# STM32MP13xx register map
File version: 1.5
CPU: CA7 r0p0, little endian, MPU, FPU, 4 interrupt priority bits
Registers are 32-bit, read-write, reset 0x0 unless marked. A register's access mark holds for its fields unless they carry their own. Offsets are from the block's base; [hi:lo] are bit positions; {n}, {i} and the like mark numbered series; 'fields as' and 'values as' point back to an identical list.

## RCC (part 4 of 7)
Base 0x50000000
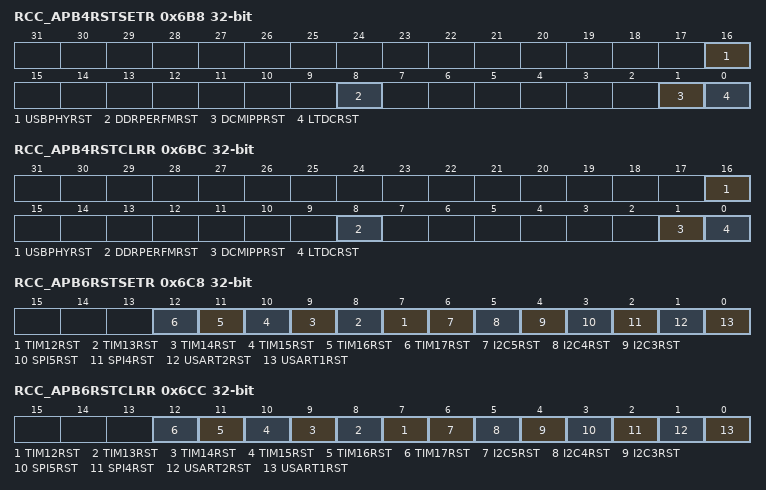
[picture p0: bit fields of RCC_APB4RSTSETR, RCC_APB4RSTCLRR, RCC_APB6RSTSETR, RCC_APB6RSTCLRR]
0x6B8 RCC_APB4RSTSETR — This register may be separately and securely write-protected at a field level, as detailed in the following register fields description. This register is used to activate the reset of the corresponding peripheral. Writing '0' has no effect, reading will return the effective values of the corresponding bits. Writing a '1' activates the reset of the corresponding peripheral.
  [all] fields
    0=Writing '0' has no effect, reading '0' means that the block reset is released; 1=Writing '1' asserts the block reset, reading '1' means that the block reset is asserted
  [16] USBPHYRST — USBPHYC block reset If USB PHY is configured as secure via the corresponding DECPROT[1] field of the ETZPC register, a write access to this register field must be secure. A read access may be secure or non-secure. Set by software.
  [8] DDRPERFMRST — DDRPERFM block reset Set by software.
  [1] DCMIPPRST — DCMIPP block reset If DCMIPP is configured as secure via the corresponding DECPROT[1] field of the ETZPC register, a write access to this register field must be secure. A read access may be secure or non-secure. Set by software.
  [0] LTDCRST — LTDC block reset If LTDC is configured as secure via the corresponding DECPROT[1] field of the ETZPC register, a write access to this register field must be secure. A read access may be secure or non-secure. Set by software.
0x6BC RCC_APB4RSTCLRR — This register may be separately and securely write-protected at a field level, as detailed in the following register fields description. This register is used to release the reset of the corresponding peripheral. Writing '0' has no effect, reading will return the effective values of the corresponding bits. Writing a '1' releases the reset of the corresponding peripheral.
  [all] fields
    0=Writing '0' has no effect, reading '0' means that the block reset is released; 1=Writing '1' releases the block reset, reading '1' means that the block reset is asserted
  [16] USBPHYRST — USBPHYC block reset If USB PHY is configured as secure via the corresponding DECPROT[1] field of the ETZPC register, a write access to this register field must be secure. A read access may be secure or non-secure. Cleared by software.
  [8] DDRPERFMRST — DDRPERFM block reset Cleared by software.
  [1] DCMIPPRST — DCMIPP block reset If DCMIPP is configured as secure via the corresponding DECPROT[1] field of the ETZPC register, a write access to this register field must be secure. A read access may be secure or non-secure. Cleared by software.
  [0] LTDCRST — LTDC block reset If LTDC is configured as secure via the corresponding DECPROT[1] field of the ETZPC register, a write access to this register field must be secure. A read access may be secure or non-secure. Cleared by software.
0x6C0 RCC_APB5RSTSETR — This register may be separately and securely write-protected at a field level depending on the secure state of the corresponding peripheral, i.e. depending on the corresponding DECPROT[1] field of the ETZPC register. This register is used to activate the reset of the corresponding peripheral. Writing '0' has no effect, reading will return the effective values of the corresponding bits. Writing a '1' activates the reset of the corresponding peripheral.
  [20] STGENRST — STGEN block reset If STGENC (STGEN controller sub-part) is configured as secure via the corresponding DECPROT[1] field of the ETZPC register, a write access to this register field must be secure. A read access may be secure or non-secure. Set by software.
    values as the fields of RCC_APB4RSTSETR
0x6C4 RCC_APB5RSTCLRR — This register may be separately and securely write-protected at a field level depending on the secure state of the corresponding peripheral, i.e. depending on the corresponding DECPROT[1] field of the ETZPC register. This register is used to release the reset of the corresponding peripheral. Writing '0' has no effect, reading will return the effective values of the corresponding bits. Writing a '1' releases the reset of the corresponding peripheral.
  [20] STGENRST — STGEN block reset If STGENC (STGEN controller sub-part) is configured as secure via the corresponding DECPROT[1] field of the ETZPC register, a write access to this register field must be secure. A read access may be secure or non-secure. Cleared by software.
    values as the fields of RCC_APB4RSTCLRR
0x6C8 RCC_APB6RSTSETR — This register may be separately and securely write-protected at a field level depending on the secure state of the corresponding peripheral, i.e. depending on the corresponding DECPROT[1] field of the ETZPC register. This register is used to activate the reset of the corresponding peripheral. Writing '0' has no effect, reading will return the effective values of the corresponding bits. Writing a '1' activates the reset of the corresponding peripheral.
  [all] fields
    values as the fields of RCC_APB4RSTSETR
  [n-5] TIM{n}RST (n=12..17) — TIM{n} block reset If TIM{n} is configured as secure via the corresponding DECPROT[1] field of the ETZPC register, a write access to this register field must be secure. A read access may be secure or non-secure. Set by software.
  [6] I2C5RST — I2C5 block reset If I2C5 is configured as secure via the corresponding DECPROT[1] field of the ETZPC register, a write access to this register field must be secure. A read access may be secure or non-secure. Set by software.
  [5] I2C4RST — I2C4 block reset If I2C4 is configured as secure via the corresponding DECPROT[1] field of the ETZPC register, a write access to this register field must be secure. A read access may be secure or non-secure. Set by software.
  [4] I2C3RST — I2C3 block reset If I2C3 is configured as secure via the corresponding DECPROT[1] field of the ETZPC register, a write access to this register field must be secure. A read access may be secure or non-secure. Set by software.
  [3] SPI5RST — SPI5 block reset If SPI5 is configured as secure via the corresponding DECPROT[1] field of the ETZPC register, a write access to this register field must be secure. A read access may be secure or non-secure. Set by software.
  [2] SPI4RST — SPI4 block reset If SPI4 is configured as secure via the corresponding DECPROT[1] field of the ETZPC register, a write access to this register field must be secure. A read access may be secure or non-secure. Set by software.
  [1] USART2RST — USART2 block reset If USART2 is configured as secure via the corresponding DECPROT[1] field of the ETZPC register, a write access to this register field must be secure. A read access may be secure or non-secure. Set by software.
  [0] USART1RST — USART1 block reset If USART1 is configured as secure via the corresponding DECPROT[1] field of the ETZPC register, a write access to this register field must be secure. A read access may be secure or non-secure. Set by software.
0x6CC RCC_APB6RSTCLRR — This register may be separately and securely write-protected at a field level depending on the secure state of the corresponding peripheral, i.e. depending on the corresponding DECPROT[1] field of the ETZPC register. This register is used to release the reset of the corresponding peripheral. Writing '0' has no effect, reading will return the effective values of the corresponding bits. Writing a '1' releases the reset of the corresponding peripheral.
  [all] fields
    values as the fields of RCC_APB4RSTCLRR
  [n-5] TIM{n}RST (n=12..17) — TIM{n} block reset If TIM{n} is configured as secure via the corresponding DECPROT[1] field of the ETZPC register, a write access to this register field must be secure. A read access may be secure or non-secure. Set by software.
  [6] I2C5RST — I2C5 block reset If I2C5 is configured as secure via the corresponding DECPROT[1] field of the ETZPC register, a write access to this register field must be secure. A read access may be secure or non-secure. Set by software.
  [5] I2C4RST — I2C4 block reset If I2C4 is configured as secure via the corresponding DECPROT[1] field of the ETZPC register, a write access to this register field must be secure. A read access may be secure or non-secure. Set by software.
  [4] I2C3RST — I2C3 block reset If I2C3 is configured as secure via the corresponding DECPROT[1] field of the ETZPC register, a write access to this register field must be secure. A read access may be secure or non-secure. Set by software.
  [3] SPI5RST — SPI5 block reset If SPI5 is configured as secure via the corresponding DECPROT[1] field of the ETZPC register, a write access to this register field must be secure. A read access may be secure or non-secure. Set by software.
  [2] SPI4RST — SPI4 block reset If SPI4 is configured as secure via the corresponding DECPROT[1] field of the ETZPC register, a write access to this register field must be secure. A read access may be secure or non-secure. Set by software.
  [1] USART2RST — USART2 block reset If USART2 is configured as secure via the corresponding DECPROT[1] field of the ETZPC register, a write access to this register field must be secure. A read access may be secure or non-secure. Set by software.
  [0] USART1RST — USART1 block reset If USART1 is configured as secure via the corresponding DECPROT[1] field of the ETZPC register, a write access to this register field must be secure. A read access may be secure or non-secure. Set by software.
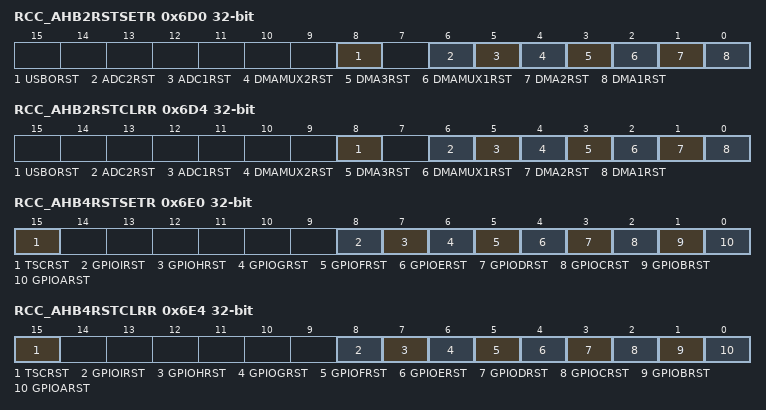
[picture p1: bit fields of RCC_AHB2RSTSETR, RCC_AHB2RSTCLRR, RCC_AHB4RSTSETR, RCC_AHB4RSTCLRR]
0x6D0 RCC_AHB2RSTSETR — This register may be separately and securely write-protected at a field level depending on the secure state of the corresponding peripheral, i.e. depending on the corresponding DECPROT[1] field of the ETZPC register. This register is used to activate the reset of the corresponding peripheral. Writing '0' has no effect, reading will return the effective values of the corresponding bits. Writing a '1' activates the reset of the corresponding peripheral.
  [all] fields
    values as the fields of RCC_APB4RSTSETR
  [8] USBORST — USBO block reset If USBO is configured as secure via the corresponding DECPROT[1] field of the ETZPC register, a write access to this register field must be secure. A read access may be secure or non-secure. Set by software.
  [6] ADC2RST — ADC2 block reset If ADC2 is configured as secure via the corresponding DECPROT[1] field of the ETZPC register, a write access to this register field must be secure. A read access may be secure or non-secure. Set by software.
  [5] ADC1RST — ADC1 block reset If ADC1 is configured as secure via the corresponding DECPROT[1] field of the ETZPC register, a write access to this register field must be secure. A read access may be secure or non-secure. Set by software.
  [4] DMAMUX2RST — DMAMUX2 block reset If DMAMUX2 is configured as secure via the corresponding DECPROT[1] field of the ETZPC register, a write access to this register field must be secure. A read access may be secure or non-secure. Set by software.
  [3] DMA3RST — DMA3 block reset If DMA3 is configured as secure via the corresponding DECPROT[1] field of the ETZPC register, a write access to this register field must be secure. A read access may be secure or non-secure. Set by software.
  [2] DMAMUX1RST — DMAMUX1 block reset Set by software.
  [1] DMA2RST — DMA2 block reset Set by software.
  [0] DMA1RST — DMA1 block reset Set by software.
0x6D4 RCC_AHB2RSTCLRR — This register may be separately and securely write-protected at a field level depending on the secure state of the corresponding peripheral, i.e. depending on the corresponding DECPROT[1] field of the ETZPC register. This register is used to release the reset of the corresponding peripheral. Writing '0' has no effect, reading will return the effective values of the corresponding bits. Writing a '1' releases the reset of the corresponding peripheral.
  [all] fields
    values as the fields of RCC_APB4RSTCLRR
  [8] USBORST — USBO block reset If USBO is configured as secure via the corresponding DECPROT[1] field of the ETZPC register, a write access to this register field must be secure. A read access may be secure or non-secure. Cleared by software.
  [6] ADC2RST — ADC2 block reset If ADC2 is configured as secure via the corresponding DECPROT[1] field of the ETZPC register, a write access to this register field must be secure. A read access may be secure or non-secure. Cleared by software.
  [5] ADC1RST — ADC1 block reset If ADC1 is configured as secure via the corresponding DECPROT[1] field of the ETZPC register, a write access to this register field must be secure. A read access may be secure or non-secure. Cleared by software.
  [4] DMAMUX2RST — DMAMUX2 block reset If DMAMUX2 is configured as secure via the corresponding DECPROT[1] field of the ETZPC register, a write access to this register field must be secure. A read access may be secure or non-secure. Cleared by software.
  [3] DMA3RST — DMA3 block reset If DMA3 is configured as secure via the corresponding DECPROT[1] field of the ETZPC register, a write access to this register field must be secure. A read access may be secure or non-secure. Cleared by software.
  [2] DMAMUX1RST — DMAMUX1 block reset Cleared by software.
  [1] DMA2RST — DMA2 block reset Cleared by software.
  [0] DMA1RST — DMA1 block reset Cleared by software.
0x6E0 RCC_AHB4RSTSETR — This register may be separately and securely write-protected at a field level, as detailed in the following register fields description. This register is used to activate the reset of the corresponding peripheral. Writing '0' has no effect, reading will return the effective values of the corresponding bits. Writing a '1' activates the reset of the corresponding peripheral.
  [all] fields
    values as the fields of RCC_APB4RSTSETR
  [15] TSCRST — TSC block reset If TSC is configured as secure via the corresponding DECPROT[1] field of the ETZPC register, a write access to this register field must be secure. A read access may be secure or non-secure. Set by software.
  [8] GPIOIRST — GPIOI block reset A write access to this register field must be secure. A read access may be secure or non-secure. Set by (secure) software.
  [7] GPIOHRST — GPIOH block reset A write access to this register field must be secure. A read access may be secure or non-secure. Set by (secure) software.
  [6] GPIOGRST — GPIOG block reset A write access to this register field must be secure. A read access may be secure or non-secure. Set by (secure) software.
  [5] GPIOFRST — GPIOF block reset A write access to this register field must be secure. A read access may be secure or non-secure. Set by (secure) software.
  [4] GPIOERST — GPIOE block reset A write access to this register field must be secure. A read access may be secure or non-secure. Set by (secure) software.
  [3] GPIODRST — GPIOD block reset A write access to this register field must be secure. A read access may be secure or non-secure. Set by (secure) software.
  [2] GPIOCRST — GPIOC block reset A write access to this register field must be secure. A read access may be secure or non-secure. Set by (secure) software.
  [1] GPIOBRST — GPIOB block reset A write access to this register field must be secure. A read access may be secure or non-secure. Set by (secure) software.
  [0] GPIOARST — GPIOA block reset A write access to this register field must be secure. A read access may be secure or non-secure. Set by (secure) software.
0x6E4 RCC_AHB4RSTCLRR — This register may be separately and securely write-protected at a field level, as detailed in the following register fields description. This register is used to release the reset of the corresponding peripheral. Writing '0' has no effect, reading will return the effective values of the corresponding bits. Writing a '1' releases the reset of the corresponding peripheral.
  [all] fields
    values as the fields of RCC_APB4RSTCLRR
  [15] TSCRST — TSC block reset If TSC is configured as secure via the corresponding DECPROT[1] field of the ETZPC register, a write access to this register field must be secure. A read access may be secure or non-secure. Cleared by software.
  [8] GPIOIRST — GPIOI block reset A write access to this register field must be secure. A read access may be secure or non-secure. Cleared by (secure) software.
  [7] GPIOHRST — GPIOH block reset A write access to this register field must be secure. A read access may be secure or non-secure. Cleared by (secure) software.
  [6] GPIOGRST — GPIOG block reset A write access to this register field must be secure. A read access may be secure or non-secure. Cleared by (secure) software.
  [5] GPIOFRST — GPIOF block reset A write access to this register field must be secure. A read access may be secure or non-secure. Cleared by (secure) software.
  [4] GPIOERST — GPIOE block reset A write access to this register field must be secure. A read access may be secure or non-secure. Cleared by (secure) software.
  [3] GPIODRST — GPIOD block reset A write access to this register field must be secure. A read access may be secure or non-secure. Cleared by (secure) software.
  [2] GPIOCRST — GPIOC block reset A write access to this register field must be secure. A read access may be secure or non-secure. Cleared by (secure) software.
  [1] GPIOBRST — GPIOB block reset A write access to this register field must be secure. A read access may be secure or non-secure. Cleared by (secure) software.
  [0] GPIOARST — GPIOA block reset A write access to this register field must be secure. A read access may be secure or non-secure. Cleared by (secure) software.
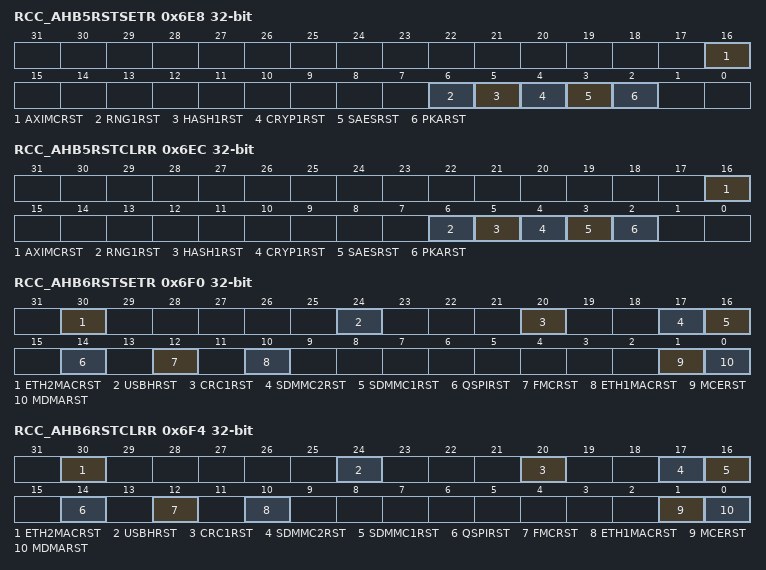
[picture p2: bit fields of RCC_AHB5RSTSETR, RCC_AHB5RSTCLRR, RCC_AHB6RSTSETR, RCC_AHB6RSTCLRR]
0x6E8 RCC_AHB5RSTSETR — This register may be separately and securely write-protected at a field level, as detailed in the following register fields description. This register is used to activate the reset of the corresponding peripheral. Writing '0' has no effect, reading will return the effective values of the corresponding bits. Writing a '1' activates the reset of the corresponding peripheral.
  [all] fields
    values as the fields of RCC_APB4RSTSETR
  [16] AXIMCRST — AXIMC block reset A write access to this register field must be secure. A read access may be secure or non-secure. Set by (secure) software.
  [6] RNG1RST — RNG1 block reset If RNG1 is configured as secure via the corresponding DECPROT[1] field of the ETZPC register, a write access to this register field must be secure. A read access may be secure or non-secure. Set by software.
  [5] HASH1RST — HASH block reset If HASH is configured as secure via the corresponding DECPROT[1] field of the ETZPC register, a write access to this register field must be secure. A read access may be secure or non-secure. Set by software.
  [4] CRYP1RST — CRYP (3DES/AES) block reset If CRYP is configured as secure via the corresponding DECPROT[1] field of the ETZPC register, a write access to this register field must be secure. A read access may be secure or non-secure. Set by software.
  [3] SAESRST — SAES block reset If SAES is configured as secure via the corresponding DECPROT[1] field of the ETZPC register, a write access to this register field must be secure. A read access may be secure or non-secure. Set by software.
  [2] PKARST — PKA block reset If PKA is configured as secure via the corresponding DECPROT[1] field of the ETZPC register, a write access to this register field must be secure. A read access may be secure or non-secure. Set by software.
0x6EC RCC_AHB5RSTCLRR — This register may be separately and securely write-protected at a field level, as detailed in the following register fields description. This register is used to release the reset of the corresponding peripheral. Writing '0' has no effect, reading will return the effective values of the corresponding bits. Writing a '1' releases the reset of the corresponding peripheral.
  [all] fields
    values as the fields of RCC_APB4RSTCLRR
  [16] AXIMCRST — AXIMC block reset A write access to this register field must be secure. A read access may be secure or non-secure. Cleared by (secure) software.
  [6] RNG1RST — RNG1 block reset If RNG1 is configured as secure via the corresponding DECPROT[1] field of the ETZPC register, a write access to this register field must be secure. A read access may be secure or non-secure. Cleared by software.
  [5] HASH1RST — HASH block reset If HASH is configured as secure via the corresponding DECPROT[1] field of the ETZPC register, a write access to this register field must be secure. A read access may be secure or non-secure. Cleared by software.
  [4] CRYP1RST — CRYP (3DES/AES) block reset If CRYP is configured as secure via the corresponding DECPROT[1] field of the ETZPC register, a write access to this register field must be secure. A read access may be secure or non-secure. Cleared by software.
  [3] SAESRST — SAES block reset If SAES is configured as secure via the corresponding DECPROT[1] field of the ETZPC register, a write access to this register field must be secure. A read access may be secure or non-secure. Cleared by software.
  [2] PKARST — PKA block reset If PKA is configured as secure via the corresponding DECPROT[1] field of the ETZPC register, a write access to this register field must be secure. A read access may be secure or non-secure. Cleared by software.
0x6F0 RCC_AHB6RSTSETR — This register may be separately and securely write-protected at a field level, as detailed in the following register fields description. This register is used to activate the reset of the corresponding peripheral. Writing '0' has no effect, reading will return the effective values of the corresponding bits. Writing a '1' activates the reset of the corresponding peripheral.
  [all] fields
    values as the fields of RCC_APB4RSTSETR
  [30] ETH2MACRST — ETH2 MAC block reset If ETH2 MAC is configured as secure via the corresponding DECPROT[1] field of the ETZPC register, a write access to this register field must be secure. A read access may be secure or non-secure. Set by software.
  [24] USBHRST — USBH block reset Set by software.
  [20] CRC1RST — CRC block reset Set by software.
  [17] SDMMC2RST — SDMMC2 and the SDMMC2 delay (DLYBSD2) block reset If SDMMC2 is configured as secure via the corresponding DECPROT[1] field of the ETZPC register, a write access to this register field must be secure. A read access may be secure or non-secure. Set by software.
  [16] SDMMC1RST — SDMMC1 and the SDMMC1 delay (DLYBSD1) block reset If SDMMC1 is configured as secure via the corresponding DECPROT[1] field of the ETZPC register, a write access to this register field must be secure. A read access may be secure or non-secure. Set by software.
  [14] QSPIRST — QUADSPI and the QUADSPI delay block reset If QSPI is configured as secure via the corresponding DECPROT[1] field of the ETZPC register, a write access to this register field must be secure. A read access may be secure or non-secure. Set by software.
  [12] FMCRST — FMC block reset If FMC is configured as secure via the corresponding DECPROT[1] field of the ETZPC register, a write access to this register field must be secure. A read access may be secure or non-secure. Set by software.
  [10] ETH1MACRST — ETH1 MAC block reset If ETH1 MAC is configured as secure via the corresponding DECPROT[1] field of the ETZPC register, a write access to this register field must be secure. A read access may be secure or non-secure. Set by software.
  [1] MCERST — MCE block reset If MCE is configured as secure via the corresponding DECPROT[1] field of the ETZPC register, a write access to this register field must be secure. A read access may be secure or non-secure. Set by software.
  [0] MDMARST — MDMA block reset A write access to this register field must be secure. A read access may be secure or non-secure. Set by (secure) software.
0x6F4 RCC_AHB6RSTCLRR — This register may be separately and securely write-protected at a field level depending on the secure state of the corresponding peripheral, i.e. depending on the corresponding DECPROT[1] field of the ETZPC register. This register is used to release the reset of the corresponding peripheral. Writing '0' has no effect, reading will return the effective values of the corresponding bits. Writing a '1' releases the reset of the corresponding peripheral.
  [all] fields
    values as the fields of RCC_APB4RSTCLRR
  [30] ETH2MACRST — ETH2 MAC block reset If ETH2 is configured as secure via the corresponding DECPROT[1] field of the ETZPC register, a write access to this register field must be secure. A read access may be secure or non-secure. Cleared by software.
  [24] USBHRST — USBH block reset Cleared by software.
  [20] CRC1RST — CRC block reset Cleared by software.
  [17] SDMMC2RST — SDMMC2 and the SDMMC2 delay (DLYBSD2) block reset If SDMMC2 is configured as secure via the corresponding DECPROT[1] field of the ETZPC register, a write access to this register field must be secure. A read access may be secure or non-secure. Cleared by software.
  [16] SDMMC1RST — SDMMC1 and the SDMMC1 delay (DLYBSD1) block reset If SDMMC1 is configured as secure via the corresponding DECPROT[1] field of the ETZPC register, a write access to this register field must be secure. A read access may be secure or non-secure. Cleared by software.
  [14] QSPIRST — QUADSPI and the QUADSPI delay block reset If QSPI is configured as secure via the corresponding DECPROT[1] field of the ETZPC register, a write access to this register field must be secure. A read access may be secure or non-secure. Cleared by software.
  [12] FMCRST — FMC block reset If FMC is configured as secure via the corresponding DECPROT[1] field of the ETZPC register, a write access to this register field must be secure. A read access may be secure or non-secure. Cleared by software.
  [10] ETH1MACRST — ETH1 MAC block reset If ETH1 MAC is configured as secure via the corresponding DECPROT[1] field of the ETZPC register, a write access to this register field must be secure. A read access may be secure or non-secure. Cleared by software.
  [1] MCERST — MCE block reset If MCE is configured as secure via the corresponding DECPROT[1] field of the ETZPC register, a write access to this register field must be secure. A read access may be secure or non-secure. Cleared by software.
  [0] MDMARST — MDMA block reset A write access to this register field must be secure. A read access may be secure or non-secure. Cleared by (secure) software.
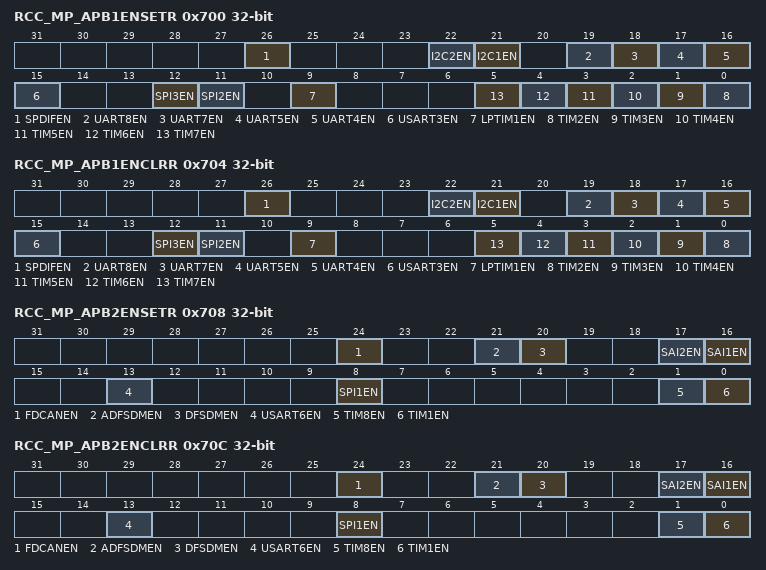
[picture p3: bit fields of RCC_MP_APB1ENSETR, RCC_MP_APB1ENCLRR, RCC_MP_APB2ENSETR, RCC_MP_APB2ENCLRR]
0x700 RCC_MP_APB1ENSETR — This register is used to set the peripheral clock enable bit of the corresponding peripheral. It shall be used to allocate a peripheral. Writing '0' has no effect, reading will return the effective value of the corresponding bits. Writing a '1' sets the corresponding bit to '1'.
  [all] fields
    0=Writing '0' has no effect, reading '0' means that the peripheral clocks are disabled; 1=Writing '1' enables the peripheral clocks, reading '1' means that the peripheral clocks are enabled
  [26] SPDIFEN — SPDIFRX peripheral clocks enable Set by software.
  [22] I2C2EN — I2C2 peripheral clocks enable Set by software.
  [21] I2C1EN — I2C1 peripheral clocks enable Set by software.
  [19] UART8EN — UART8 peripheral clocks enable Set by software.
  [18] UART7EN — UART7 peripheral clocks enable Set by software.
  [17] UART5EN — UART5 peripheral clocks enable Set by software.
  [16] UART4EN — UART4 peripheral clocks enable Set by software.
  [15] USART3EN — USART3 peripheral clocks enable Set by software.
  [12] SPI3EN — SPI3 peripheral clocks enable Set by software.
  [11] SPI2EN — SPI2 peripheral clocks enable Set by software.
  [9] LPTIM1EN — LPTIM1 peripheral clocks enable Set by software.
  [n-2] TIM{n}EN (n=2..7) — TIM{n} peripheral clocks enable Set by software.
0x704 RCC_MP_APB1ENCLRR — This register is used to clear the peripheral clock enable bit of the corresponding peripheral. It shall be used to deallocate a peripheral. Writing '0' has no effect, reading will return the effective values of the corresponding bits. Writing a '1' sets the corresponding bit to '0'.
  [all] fields
    0=Writing '0' has no effect, reading '0' means that the peripheral clocks are disabled; 1=Writing '1' disables the peripheral clocks, reading '1' means that the peripheral clocks are enabled
  [26] SPDIFEN — SPDIFRX peripheral clocks enable Cleared by software.
  [22] I2C2EN — I2C2 peripheral clocks enable Cleared by software.
  [21] I2C1EN — I2C1 peripheral clocks enable Cleared by software.
  [19] UART8EN — UART8 peripheral clocks enable Cleared by software.
  [18] UART7EN — UART7 peripheral clocks enable Cleared by software.
  [17] UART5EN — UART5 peripheral clocks enable Cleared by software.
  [16] UART4EN — UART4 peripheral clocks enable Cleared by software.
  [15] USART3EN — USART3 peripheral clocks enable Cleared by software.
  [12] SPI3EN — SPI3 peripheral clocks enable Cleared by software.
  [11] SPI2EN — SPI2 peripheral clocks enable Cleared by software.
  [9] LPTIM1EN — LPTIM1 peripheral clocks enable Cleared by software.
  [n-2] TIM{n}EN (n=2..7) — TIM{n} peripheral clocks enable Cleared by software.
0x708 RCC_MP_APB2ENSETR — This register is used to set the peripheral clock enable bit of the corresponding peripheral. It shall be used to allocate a peripheral. Writing '0' has no effect, reading will return the effective values of the corresponding bits. Writing a '1' sets the corresponding bit to '1'.
  [all] fields
    values as the fields of RCC_MP_APB1ENSETR
  [24] FDCANEN — FDCAN and CANRAM peripheral clocks enable Set by software.
  [21] ADFSDMEN — Audio DFSDM peripheral clocks enable Set by software.
  [20] DFSDMEN — DFSDM peripheral clocks enable Set by software.
  [17] SAI2EN — SAI2 peripheral clocks enable Set by software.
  [16] SAI1EN — SAI1 peripheral clocks enable Set by software.
  [13] USART6EN — USART6 peripheral clocks enable Set by software.
  [8] SPI1EN — SPI/I2S1 peripheral clocks enable Set by software.
  [1] TIM8EN — TIM8 peripheral clocks enable Set by software.
  [0] TIM1EN — TIM1 peripheral clocks enable Set by software.
0x70C RCC_MP_APB2ENCLRR — This register is used to clear the peripheral clock enable bit of the corresponding peripheral. It shall be used to deallocate a peripheral. Writing '0' has no effect, reading will return the effective values of the corresponding bits. Writing a '1' sets the corresponding bit to â0â.
  [all] fields
    values as the fields of RCC_MP_APB1ENCLRR
  [24] FDCANEN — FDCAN and CANRAM peripheral clocks enable Cleared by software.
  [21] ADFSDMEN — Audio DFSDM peripheral clocks enable Cleared by software.
  [20] DFSDMEN — DFSDM peripheral clocks enable Cleared by software.
  [17] SAI2EN — SAI2 peripheral clocks enable Cleared by software.
  [16] SAI1EN — SAI1 peripheral clocks enable Cleared by software.
  [13] USART6EN — USART6 peripheral clocks enable Cleared by software.
  [8] SPI1EN — SPI/I2S1 peripheral clocks enable Cleared by software.
  [1] TIM8EN — TIM8 peripheral clocks enable Cleared by software.
  [0] TIM1EN — TIM1 peripheral clocks enable Cleared by software.
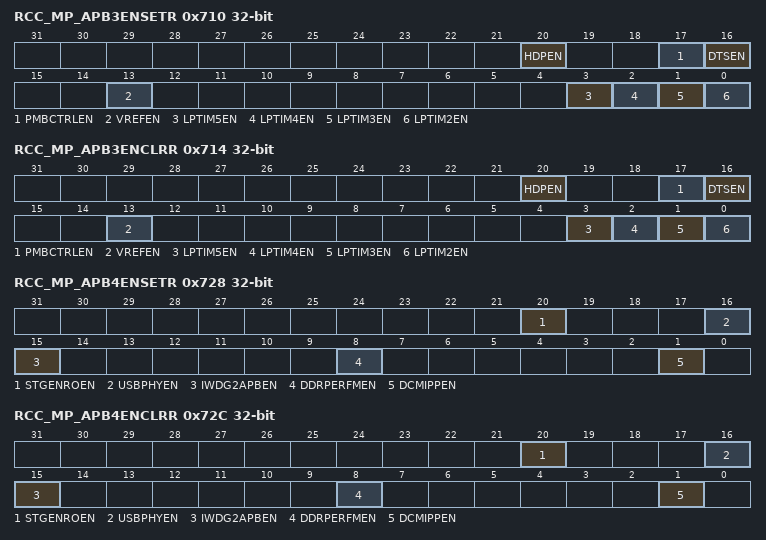
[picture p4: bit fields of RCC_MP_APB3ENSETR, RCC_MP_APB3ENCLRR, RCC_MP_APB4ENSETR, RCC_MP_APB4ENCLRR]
0x710 RCC_MP_APB3ENSETR — This register may be separately and securely write-protected at a field level, as detailed in the following register fields description. This register is used to set the peripheral clock enable bit of the corresponding peripheral. It shall be used to allocate a peripheral. Writing '0' has no effect, reading will return the effective values of the corresponding bits. Writing a '1' sets the corresponding bit to '1'.
  [20] HDPEN — HDP peripheral clocks enable Set by software.
    values as the fields of RCC_MP_APB1ENSETR
  [17] PMBCTRLEN — PMBCTRL peripheral clocks enable (non-user): this bit is present in the RTL and is internally used as: SPIRIT parameter RTLPRESENT
  [16] DTSEN — DTS peripheral clocks enable Set by software.
    values as the fields of RCC_MP_APB1ENSETR
  [13] VREFEN — VREF peripheral clocks enable If VREF block is configured as secure via the corresponding DECPROT[1] field of the ETZPC register, a write access to this register field must be secure. A read access may be secure or non-secure. Set by software.
    values as the fields of RCC_MP_APB1ENSETR
  [3] LPTIM5EN — LPTIM5 peripheral clocks enable Set by software.
    values as the fields of RCC_MP_APB1ENSETR
  [2] LPTIM4EN — LPTIM4 peripheral clocks enable Set by software.
    values as the fields of RCC_MP_APB1ENSETR
  [1] LPTIM3EN — LPTIM3 peripheral clocks enable If LPTIM3 block is configured as secure via the corresponding DECPROT[1] field of the ETZPC register, a write access to this register field must be secure. A read access may be secure or non-secure. Set by software.
    values as the fields of RCC_MP_APB1ENSETR
  [0] LPTIM2EN — LPTIM2 peripheral clocks enable If LPTIM2 block is configured as secure via the corresponding DECPROT[1] field of the ETZPC register, a write access to this register field must be secure. A read access may be secure or non-secure. Set by software.
    values as the fields of RCC_MP_APB1ENSETR
0x714 RCC_MP_APB3ENCLRR — This register may be separately and securely write-protected at a field level, as detailed in the following register fields description. This register is used to clear the peripheral clock enable bit of the corresponding peripheral. It shall be used to deallocate a peripheral. Writing '0' has no effect, reading will return the effective values of the corresponding bits. Writing a '1' sets the corresponding bit to '0'.
  [20] HDPEN — HDP peripheral clocks enable Cleared by software.
    values as the fields of RCC_MP_APB1ENCLRR
  [17] PMBCTRLEN — PMBCTRL peripheral clocks enable (non-user): this bit is present in the RTL and is internally used as: SPIRIT parameter RTLPRESENT
  [16] DTSEN — DTS peripheral clocks enable Cleared by software.
    values as the fields of RCC_MP_APB1ENCLRR
  [13] VREFEN — VREF peripheral clocks enable If VREF block is configured as secure via the corresponding DECPROT[1] field of the ETZPC register, a write access to this register field must be secure. A read access may be secure or non-secure. Cleared by software.
    values as the fields of RCC_MP_APB1ENCLRR
  [3] LPTIM5EN — LPTIM5 peripheral clocks enable Cleared by software.
    values as the fields of RCC_MP_APB1ENCLRR
  [2] LPTIM4EN — LPTIM4 peripheral clocks enable Cleared by software.
    values as the fields of RCC_MP_APB1ENCLRR
  [1] LPTIM3EN — LPTIM3 peripheral clocks enable If LPTIM3 block is configured as secure via the corresponding DECPROT[1] field of the ETZPC register, a write access to this register field must be secure. A read access may be secure or non-secure. Cleared by software.
    values as the fields of RCC_MP_APB1ENCLRR
  [0] LPTIM2EN — LPTIM2 peripheral clocks enable If LPTIM2 block is configured as secure via the corresponding DECPROT[1] field of the ETZPC register, a write access to this register field must be secure. A read access may be secure or non-secure. Cleared by software.
    values as the fields of RCC_MP_APB1ENCLRR
0x718 RCC_MP_S_APB3ENSETR — This is a secure register for enabling the clock of the SYSCFG.
  [0] SYSCFGEN — SYSCFG peripheral clocks enable Set by (secure) software.
    values as the fields of RCC_MP_APB1ENSETR
0x71C RCC_MP_S_APB3ENCLRR — This is a secure register for disabling the clock of the SYSCFG. A write access to this register field must be secure. A read access may be secure or non-secure. This register is used to clear the peripheral clock enable bit of the corresponding peripheral. It shall be used to deallocate a peripheral. Writing '0' has no effect, reading will return the effective values of the corresponding bits. Writing a '1' sets the corresponding bit to '0'.
  [0] SYSCFGEN — SYSCFG peripheral clocks enable Cleared by (secure) software.
    values as the fields of RCC_MP_APB1ENSETR
0x720 RCC_MP_NS_APB3ENSETR — This is a non-secure register, for enabling the clock of the SYSCFG.
  [0] SYSCFGEN — SYSCFG peripheral clocks enable Set by software.
    values as the fields of RCC_MP_APB1ENSETR
0x724 RCC_MP_NS_APB3ENCLRR — This is a non-secure register, for disabling the clock of the SYSCFG.
  [0] SYSCFGEN — SYSCFG peripheral clocks enable Cleared by software.
    values as the fields of RCC_MP_APB1ENCLRR
0x728 RCC_MP_APB4ENSETR — This register may be separately and securely write-protected at a field level, as detailed in the following register fields description. This register is used to set the peripheral clock enable bit of the corresponding peripheral. It shall be used to allocate a peripheral. Writing '0' has no effect, reading will return the effective values of the corresponding bits. Writing a '1' sets the corresponding bit to '1'.
  [20] STGENROEN — STGEN read-only interface peripheral clocks enable Set by software. The peripheral clocks of the STGEN read-only interface are the pclk4, and the kernel clock as selected by the RCC_STGENCKSELR register.
    0=Writing '0' has no effect, reading '0' means that the pclk4 is disabled, and that the kernel clock gating is defined by RCC_MP_APB5ENxxxR.STGENCEN with xxx=SET/CLR; 1=Writing '1' enables the pclk4 and the kernel clock; reading '1' means that the pck4 and the kernel clock are enabled
  [16] USBPHYEN — USBPHYC peripheral clocks enable If USB PHY is configured as secure via the corresponding DECPROT[1] field of the ETZPC register, a write access to this register field must be secure. A read access may be secure or non-secure. Set by software.
    values as the fields of RCC_MP_APB1ENSETR
  [15] IWDG2APBEN — IWDG2 APB clock enable Set by software.
    0=Writing '0' has no effect, reading '0' means that the APB clock is disabled; 1=Writing '1' enables the APB clock, reading '1' means that the APB clock is enabled
  [8] DDRPERFMEN — DDRPERFM APB clock enable Set by software.
    values as IWDG2APBEN
  [1] DCMIPPEN — DCMIPP peripheral clocks enable If DCMIPP is configured as secure via the corresponding DECPROT[1] field of the ETZPC register, a write access to this register field must be secure. A read access may be secure or non-secure. Set by software.
    values as the fields of RCC_MP_APB1ENSETR
0x72C RCC_MP_APB4ENCLRR — This register may be separately and securely write-protected at a field level, as detailed in the following register fields description. This register is used to clear the peripheral clock enable bit of the corresponding peripheral. It shall be used to deallocate a peripheral. Writing '0' has no effect, reading will return the effective values of the corresponding bits. Writing a '1' sets the corresponding bit to '0'.
  [20] STGENROEN — STGEN read-only interface peripheral clocks enable Cleared by software. The peripheral clocks of the STGEN read-only interface are the pclk4, and the kernel clock as selected by the RCC_STGENCKSELR register.
    0=Writing '0' has no effect, reading '0' means that the pclk4 is disabled, and that the kernel clock gating is defined by RCC_MP_APB5ENxxxR.STGENCEN with xxx=SET/CLR; 1=Writing '1' disables the pclk4, and disables the kernel clock provided that RCC_MP_APB5ENSETR.STGENCEN=0 else it has no effect; reading '1' means that the pck4 and the kernel clock are enabled
  [16] USBPHYEN — USBPHYC peripheral clocks enable If USB PHY is configured as secure via the corresponding DECPROT[1] field of the ETZPC register, a write access to this register field must be secure. A read access may be secure or non-secure. Cleared by software.
    values as the fields of RCC_MP_APB1ENCLRR
  [15] IWDG2APBEN — IWDG2 APB clock enable Cleared by software.
    0=Writing '0' has no effect, reading '0' means that the APB clock is disabled; 1=Writing '1' disables the APB clock, reading '1' means that the APB clock is enabled
  [8] DDRPERFMEN — DDRPERFM APB clock enable Cleared by software.
    values as IWDG2APBEN
  [1] DCMIPPEN — DCMIPP peripheral clocks enable If DCMIPP is configured as secure via the corresponding DECPROT[1] field of the ETZPC register, a write access to this register field must be secure. A read access may be secure or non-secure. Cleared by software.
    values as the fields of RCC_MP_APB1ENCLRR
